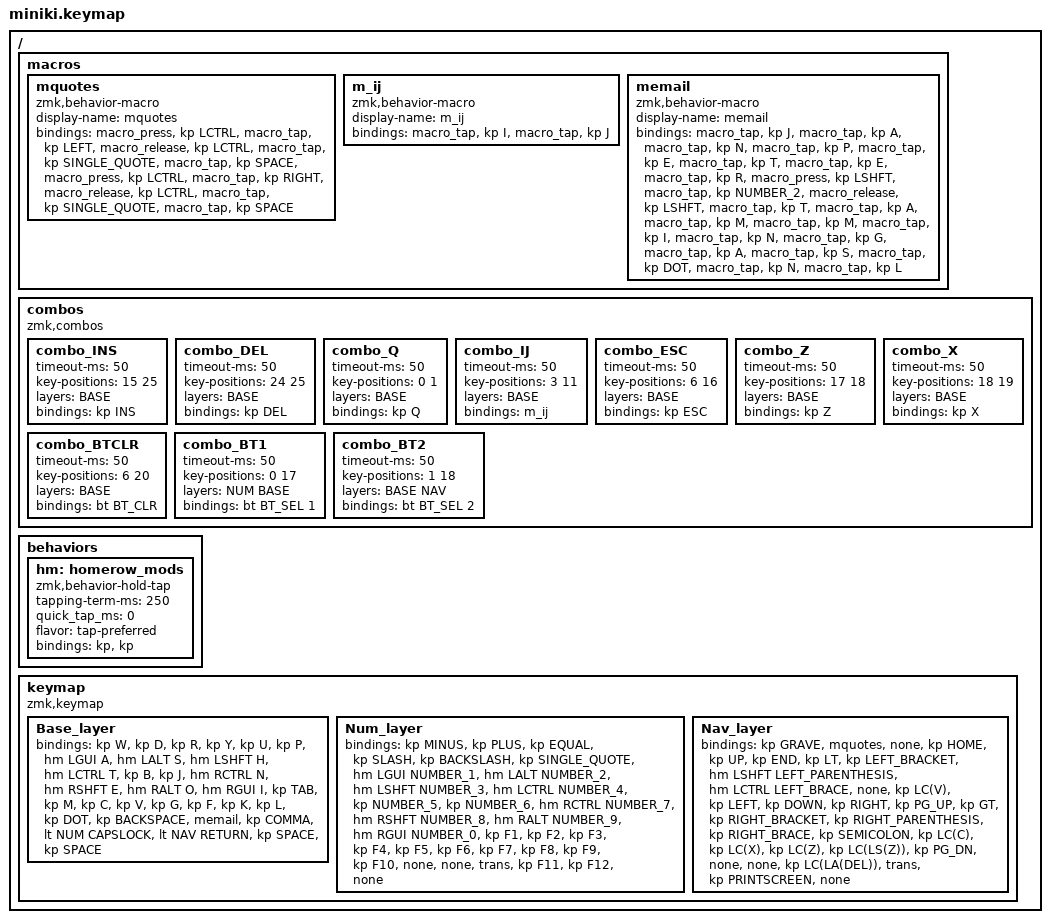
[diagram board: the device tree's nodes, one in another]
#include <behaviors.dtsi>
#include <dt-bindings/zmk/keys.h>
#include <dt-bindings/zmk/bt.h>

#define BASE 0
#define NUM 1
#define NAV 2

/ {
  macros {
    mquotes: mquotes {
      display-name = "mquotes";
      compatible = "zmk,behavior-macro";
      #binding-cells = <0>;
      bindings
        = <&macro_press &kp LCTRL>
        , <&macro_tap &kp LEFT>
        , <&macro_release &kp LCTRL>
        , <&macro_tap &kp SINGLE_QUOTE>
        , <&macro_tap &kp SPACE>
        , <&macro_press &kp LCTRL>
        , <&macro_tap &kp RIGHT>
        , <&macro_release &kp LCTRL>
        , <&macro_tap &kp SINGLE_QUOTE>
        , <&macro_tap &kp SPACE>
        ;
    };

    m_ij: m_ij {
      display-name = "m_ij";
      compatible = "zmk,behavior-macro";
      #binding-cells = <0>;
      bindings
        = <&macro_tap &kp I>
        , <&macro_tap &kp J>
        ;
    };

    memail: memail {
          display-name = "memail";
          compatible = "zmk,behavior-macro";
          #binding-cells = <0>;
          bindings
            = <&macro_tap &kp J>
            , <&macro_tap &kp A>
            , <&macro_tap &kp N>
            , <&macro_tap &kp P>
            , <&macro_tap &kp E>
            , <&macro_tap &kp T>
            , <&macro_tap &kp E>
            , <&macro_tap &kp R>
            , <&macro_press &kp LSHFT>
            , <&macro_tap &kp NUMBER_2>
            , <&macro_release &kp LSHFT>
            , <&macro_tap &kp T>
            , <&macro_tap &kp A>
            , <&macro_tap &kp M>
            , <&macro_tap &kp M>
            , <&macro_tap &kp I>
            , <&macro_tap &kp N>
            , <&macro_tap &kp G>
            , <&macro_tap &kp A>
            , <&macro_tap &kp S>
            , <&macro_tap &kp DOT>
            , <&macro_tap &kp N>
            , <&macro_tap &kp L>;
        };
  };

  combos {
    compatible = "zmk,combos";

    combo_INS {
      timeout-ms = <50>;
      key-positions = <15 25>;
      layers = <BASE>;
      bindings = <&kp INS>;
    };

    combo_DEL {
      timeout-ms = <50>;
      key-positions = <24 25>;
      layers = <BASE>;
      bindings = <&kp DEL>;
    };

    combo_Q {
      timeout-ms = <50>;
      key-positions = <0 1>;
      layers = <BASE>;
      bindings = <&kp Q>;
    };

    combo_IJ {
      timeout-ms = <50>;
      key-positions = <3 11>;
      layers = <BASE>;
      bindings = <&m_ij>;
    };

    combo_ESC {
      timeout-ms = <50>;
      key-positions = <6 16>;
      layers = <BASE>;
      bindings = <&kp ESC>;
    };

    combo_Z {
      timeout-ms = <50>;
      key-positions = <17 18>;
      layers = <BASE>;
      bindings = <&kp Z>;
    };

    combo_X {
      timeout-ms = <50>;
      key-positions = <18 19>;
      layers = <BASE>;
      bindings = <&kp X>;
    };

    combo_BTCLR {
      timeout-ms = <50>;
      key-positions = <6 20>;
      layers = <BASE>;
      bindings = <&bt BT_CLR>;
    };

    combo_BT1 {
      timeout-ms = <50>;
      key-positions = <0 17>;
      layers = <NUM BASE>;
      bindings = <&bt BT_SEL 1>;
    };

    combo_BT2 {
      timeout-ms = <50>;
      key-positions = <1 18>;
      layers = <BASE NAV>;
      bindings = <&bt BT_SEL 2>;
    };
  };


  behaviors {
    hm: homerow_mods {
      compatible = "zmk,behavior-hold-tap";
      #binding-cells = <2>;
      tapping-term-ms = <250>;
      quick_tap_ms = <0>;
      flavor = "tap-preferred";
      bindings = <&kp>, <&kp>;
    };
  };
  keymap {
    compatible = "zmk,keymap";

    Base_layer {
      bindings = <
        &kp W &kp D &kp R &kp Y &kp U &kp P &hm LGUI A &hm LALT S &hm LSHFT H &hm LCTRL T &kp B &kp J &hm RCTRL N &hm RSHFT E &hm RALT O &hm RGUI I &kp TAB &kp M &kp C &kp V &kp G &kp F &kp K &kp L &kp DOT &kp BACKSPACE &memail &kp COMMA &lt NUM CAPSLOCK &lt NAV RETURN &kp SPACE &kp SPACE
      >;
    };

    Num_layer {
      bindings = <
        &kp MINUS &kp PLUS &kp EQUAL &kp SLASH &kp BACKSLASH &kp SINGLE_QUOTE &hm LGUI NUMBER_1 &hm LALT NUMBER_2 &hm LSHFT NUMBER_3 &hm LCTRL NUMBER_4 &kp NUMBER_5 &kp NUMBER_6 &hm RCTRL NUMBER_7 &hm RSHFT NUMBER_8 &hm RALT NUMBER_9 &hm RGUI NUMBER_0 &kp F1 &kp F2 &kp F3 &kp F4 &kp F5 &kp F6 &kp F7 &kp F8 &kp F9 &kp F10 &none &none &trans &kp F11 &kp F12 &none
      >;
    };

    Nav_layer {
      bindings = <
        &kp GRAVE &mquotes &none &kp HOME &kp UP &kp END &kp LT &kp LEFT_BRACKET &hm LSHFT LEFT_PARENTHESIS &hm LCTRL LEFT_BRACE &none &kp LC(V) &kp LEFT &kp DOWN &kp RIGHT &kp PG_UP &kp GT &kp RIGHT_BRACKET &kp RIGHT_PARENTHESIS &kp RIGHT_BRACE &kp SEMICOLON &kp LC(C) &kp LC(X) &kp LC(Z) &kp LC(LS(Z)) &kp PG_DN &none &none &kp LC(LA(DEL)) &trans &kp PRINTSCREEN &none
      >;
    };

  };
};
